# R7FA2E1A9 register map
Vendor: Renesas Electronics Corporation; Series: RA2; File version: 1.51.00
CPU: CM23 r1p0, little endian, MPU, no FPU, VTOR, 2 interrupt priority bits, 32 interrupts
Registers are 8-bit, read-write, reset 0x0 unless marked. A register's access mark holds for its fields unless they carry their own. Offsets are from the block's base; [hi:lo] are bit positions; 'fields as' and 'values as' point back to an identical list.

## MSTP — Module Stop Control B, C, D
Base 0x40047000
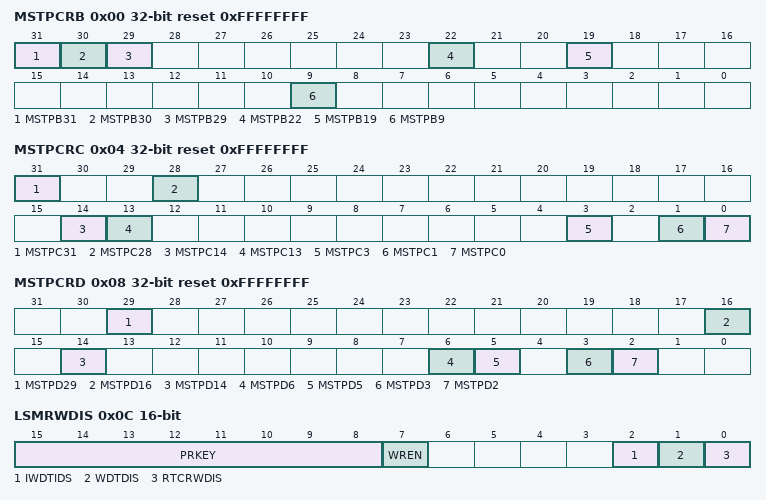
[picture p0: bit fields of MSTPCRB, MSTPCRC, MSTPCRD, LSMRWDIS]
0x00 MSTPCRB 32-bit reset 0xFFFFFFFF — Module Stop Control Register B
  [all] fields
    0=Cancel the module-stop state; 1=Enter the module-stop state
  [31] MSTPB31 — Serial Communication Interface 0 Module Stop
  [30] MSTPB30 — Serial Communication Interface 1 Module Stop
  [29] MSTPB29 — Serial Communication Interface 2 Module Stop
  [22] MSTPB22 — Serial Communication Interface 9 Module Stop
  [19] MSTPB19 — Serial Peripheral Interface 0 Module Stop
  [9] MSTPB9 — I2C Bus Interface 0 Module Stop
0x04 MSTPCRC 32-bit reset 0xFFFFFFFF — Module Stop Control Register C
  [all] fields
    values as the fields of MSTPCRB
  [31] MSTPC31 — AES Module Stop
  [28] MSTPC28 — True Random Number Generator Module Stop
  [14] MSTPC14 — Event Link Controller Module Stop
  [13] MSTPC13 — Data Operation Circuit Module Stop
  [3] MSTPC3 — Capacitive Sensing Unit Module Stop
  [1] MSTPC1 — Cyclic Redundancy Check Calculator Module Stop
  [0] MSTPC0 — Clock Frequency Accuracy Measurement Circuit Module Stop
0x08 MSTPCRD 32-bit reset 0xFFFFFFFF — Module Stop Control Register D
  [all] fields
    values as the fields of MSTPCRB
  [29] MSTPD29 — Low-Power Analog Comparator Module Stop
  [16] MSTPD16 — 12-bit A/D Converter Module Stop
  [14] MSTPD14 — Port Output Enable for GPT Module Stop
  [6] MSTPD6 — General PWM Timer 164 to 169 and PWM Delay Generation Circuit Module Stop
  [5] MSTPD5 — General PWM Timer 32n Module Stop
  [3] MSTPD3 — Low Power Asynchronous General Purpose Timer 0 Module Stop
  [2] MSTPD2 — Low Power Asynchronous General Purpose Timer 1 Module Stop
0x0C LSMRWDIS 16-bit — Low Speed Module R/W Disable Control Register
  [15:8] PRKEY wo — LSMRWDIS Key Code
  [7] WREN — Write Enable for bits [2:0]
    0=Write protect for bits [2:0]; 1=Write enable for bits [2:0]
  [2] IWDTIDS — IWDT Register Clock Control
    0=IWDT operates as normal; 1=Stop the IWDT register R/W clock
  [1] WDTDIS — WDT Operate Clock Control
    0=WDT operates as normal; 1=Stop the WDT clock and register R/W clock
  [0] RTCRWDIS — RTC Register R/W Enable Control
    0=RTC register R/W clock always on; 1=RTC register R/W clock stops

## IIC0WU — Inter-Integrated Circuit 0 Wake-up Unit
Base 0x40053014
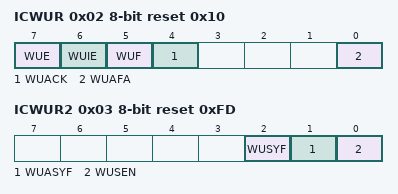
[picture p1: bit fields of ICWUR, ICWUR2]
0x02 ICWUR reset 0x10 — I2C Bus Wakeup Unit Register
  [7] WUE — Wakeup Function Enable
    0=Disable wakeup function; 1=Enable wakeup function
  [6] WUIE — Wakeup Interrupt Request Enable
    0=Disable wakeup interrupt request (IIC0_WUI); 1=Enable wakeup interrupt request (IIC0_WUI)
  [5] WUF — Wakeup Event Occurrence Flag
    0=Slave address not matching during wakeup; 1=Slave address matching during wakeup
  [4] WUACK — ACK Bit for Wakeup Mode
  [0] WUAFA — Wakeup Analog Filter Additional Selection
    0=Do not add the wakeup analog filter; 1=Add the wakeup analog filter
0x03 ICWUR2 reset 0xFD — I2C Bus Wakeup Unit Register 2
  [2] WUSYF ro — Wakeup Function Synchronous Operation Status Flag
    0=IIC asynchronous circuit enable condition; 1=IIC synchronous circuit enable condition
  [1] WUASYF ro — Wakeup Function Asynchronous Operation Status Flag
    0=IIC synchronous circuit enable condition; 1=IIC asynchronous circuit enable condition
  [0] WUSEN — Wakeup Function Synchronous Enable
    0=IIC asynchronous circuit enable; 1=IIC synchronous circuit enable

## DOC — Data Operation Circuit
Base 0x40054100
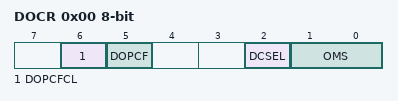
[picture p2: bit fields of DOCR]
0x00 DOCR — DOC Control Register
  [6] DOPCFCL — DOPCF Clear
    0=Retain DOPCF flag state; 1=Clear DOPCF flag
  [5] DOPCF ro — DOC Flag
  [2] DCSEL — Detection Condition Select
    0=Set DOPCF flag when data mismatch is detected; 1=Set DOPCF flag when data match is detected
  [1:0] OMS — Operating Mode Select
    0=Data comparison mode; 1=Data addition mode; 2=Data subtraction mode; 3=Setting prohibited
0x02 DODIR 16-bit — DOC Data Input Register
0x04 DODSR 16-bit — DOC Data Setting Register

## Notices in the file
This software is supplied by Renesas Electronics Corporation and is only intended for
use with Renesas products. No other uses are authorized. This software is owned by
Renesas Electronics Corporation and is protected under all applicable laws, including
copyright laws.
THIS SOFTWARE IS PROVIDED "AS IS" AND RENESAS MAKES NO WARRANTIES REGARDING
THIS SOFTWARE, WHETHER EXPRESS, IMPLIED OR STATUTORY, INCLUDING BUT NOT LIMITED TO
WARRANTIES OF MERCHANTABILITY, FITNESS FOR A PARTICULAR PURPOSE AND NON-INFRINGEMENT.
ALL SUCH WARRANTIES ARE EXPRESSLY DISCLAIMED. TO THE MAXIMUM EXTENT PERMITTED NOT
PROHIBITED BY LAW, NEITHER RENESAS ELECTRONICS CORPORATION NOR ANY OF ITS AFFILIATED
COMPANIES SHALL BE LIABLE FOR ANY DIRECT, INDIRECT, SPECIAL, INCIDENTAL OR CONSEQUENTIAL
DAMAGES FOR ANY REASON RELATED TO THIS SOFTWARE, EVEN IF RENESAS OR ITS AFFILIATES HAVE
BEEN ADVISED OF THE POSSIBILITY OF SUCH DAMAGES.
Renesas reserves the right, without notice, to make changes to this software and to
discontinue the availability of this software. By using this software, you agree to
the additional terms and conditions found by accessing the following link:
http://www.renesas.com/disclaimer
